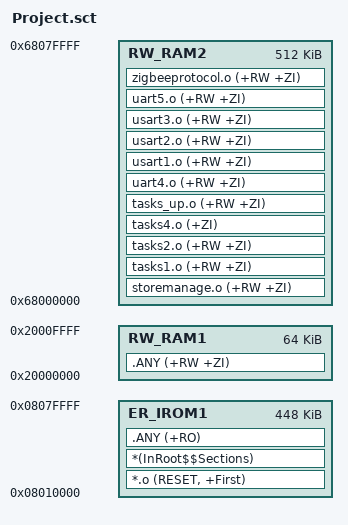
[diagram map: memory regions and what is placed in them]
; *************************************************************
; *** Scatter-Loading Description File generated by uVision ***
; *************************************************************

LR_IROM1 0x08010000 0x00070000  {    ; load region size_region
  ER_IROM1 0x08010000 0x00070000  {  ; load address = execution address
   *.o (RESET, +First)
   *(InRoot$$Sections)
   .ANY (+RO)
  }
  RW_RAM1 0x20000000 0x10000  {  ; RW data
   .ANY (+RW +ZI)
  }

  RW_RAM2 0x68000000 0x00080000  {  ; RW data
   storemanage.o (+RW +ZI)
   tasks1.o (+RW +ZI)
   tasks2.o (+RW +ZI)
   tasks4.o (+ZI)
   tasks_up.o (+RW +ZI)
   uart4.o (+RW +ZI)
   usart1.o (+RW +ZI)
   usart2.o (+RW +ZI)
   usart3.o (+RW +ZI)
   uart5.o (+RW +ZI)
   zigbeeprotocol.o (+RW +ZI)
  }

}

